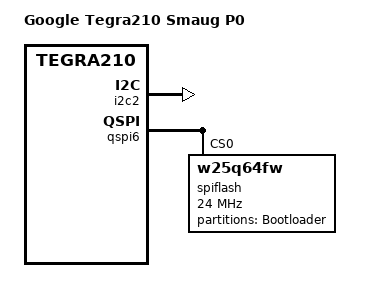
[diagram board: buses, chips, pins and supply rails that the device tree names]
/dts-v1/;

#include "tegra210-smaug.dtsi"

/ {
	model = "Google Tegra210 Smaug P0";
	compatible = "google,smaug-rev0", "google,smaug", "nvidia,tegra210";
};

// GEN2_I2C
&i2c2 {
	status = "okay";

	sensor-hub@1f {
		// TODO:
		reg = <0x1f>;
		status = "disabled";
	};
};

&qspi6 {
	spiflash@1 {
		#address-cells = <1>;
		#size-cells = <1>;
		compatible = "w25q64fw";
		reg = <0>;
		spi-max-frequency = <24000000>;
		partition@0 {
			label = "Bootloader";
			reg = <0x00000000 0x00800000>;
		};
		controller-data {
			nvidia,x1-len-limit = <16>;
			nvidia,x1-bus-speed = <24000000>;
			nvidia,x1-dummy-cycle = <0>;
			nvidia,x4-bus-speed = <24000000>;
			nvidia,x4-dummy-cycle = <8>;
		};
	};
};
